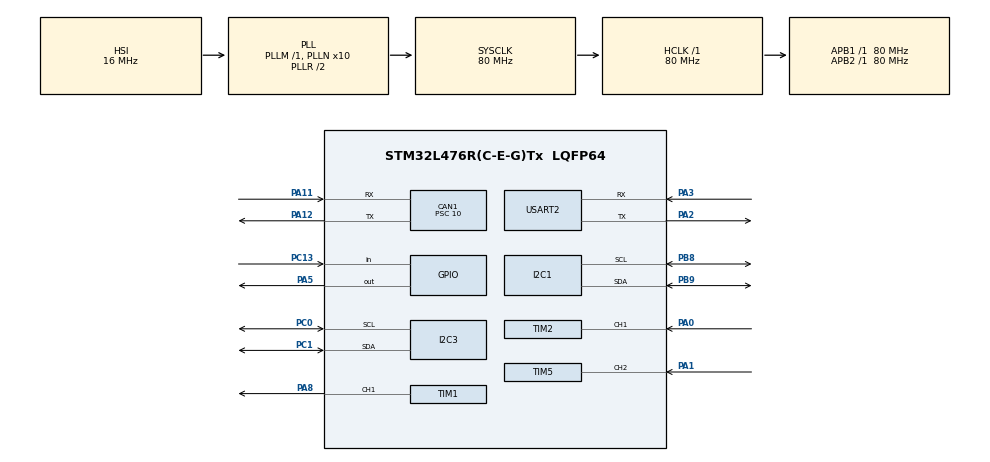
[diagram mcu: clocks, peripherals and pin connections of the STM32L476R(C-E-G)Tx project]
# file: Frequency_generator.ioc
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CAN1.BS1=CAN_BS1_13TQ
CAN1.BS2=CAN_BS2_2TQ
CAN1.CalculateBaudRate=500000
CAN1.CalculateTimeBit=2000.00
CAN1.CalculateTimeQuantum=125.0
CAN1.Prescaler=10
Dma.Request0=TIM2_CH1
Dma.Request1=TIM2_CH2/CH4
Dma.Request2=TIM5_CH1
Dma.Request3=TIM5_CH2
Dma.TIM2_CH1.0.Direction=DMA_PERIPH_TO_MEMORY
Dma.TIM2_CH1.0.Instance=DMA1_Channel5
Dma.TIM2_CH1.0.MemDataAlignment=DMA_MDATAALIGN_WORD
Dma.TIM2_CH1.0.MemInc=DMA_MINC_ENABLE
Dma.TIM2_CH1.0.Mode=DMA_NORMAL
Dma.TIM2_CH1.0.PeriphDataAlignment=DMA_PDATAALIGN_WORD
Dma.TIM2_CH1.0.PeriphInc=DMA_PINC_DISABLE
Dma.TIM2_CH1.0.Priority=DMA_PRIORITY_LOW
Dma.TIM2_CH2/CH4.1.Direction=DMA_PERIPH_TO_MEMORY
Dma.TIM2_CH2/CH4.1.Instance=DMA1_Channel7
Dma.TIM2_CH2/CH4.1.MemDataAlignment=DMA_MDATAALIGN_WORD
Dma.TIM2_CH2/CH4.1.MemInc=DMA_MINC_ENABLE
Dma.TIM2_CH2/CH4.1.Mode=DMA_NORMAL
Dma.TIM2_CH2/CH4.1.PeriphDataAlignment=DMA_PDATAALIGN_WORD
Dma.TIM2_CH2/CH4.1.PeriphInc=DMA_PINC_DISABLE
Dma.TIM2_CH2/CH4.1.Priority=DMA_PRIORITY_LOW
Dma.TIM5_CH1.2.Direction=DMA_PERIPH_TO_MEMORY
Dma.TIM5_CH1.2.Instance=DMA2_Channel5
Dma.TIM5_CH1.2.MemDataAlignment=DMA_MDATAALIGN_WORD
Dma.TIM5_CH1.2.MemInc=DMA_MINC_ENABLE
Dma.TIM5_CH1.2.Mode=DMA_NORMAL
Dma.TIM5_CH1.2.PeriphDataAlignment=DMA_PDATAALIGN_WORD
Dma.TIM5_CH1.2.PeriphInc=DMA_PINC_DISABLE
Dma.TIM5_CH1.2.Priority=DMA_PRIORITY_LOW
Dma.TIM5_CH2.3.Direction=DMA_PERIPH_TO_MEMORY
Dma.TIM5_CH2.3.Instance=DMA2_Channel4
Dma.TIM5_CH2.3.MemDataAlignment=DMA_MDATAALIGN_WORD
Dma.TIM5_CH2.3.MemInc=DMA_MINC_ENABLE
Dma.TIM5_CH2.3.Mode=DMA_NORMAL
Dma.TIM5_CH2.3.PeriphDataAlignment=DMA_PDATAALIGN_WORD
Dma.TIM5_CH2.3.PeriphInc=DMA_PINC_DISABLE
Dma.TIM5_CH2.3.Priority=DMA_PRIORITY_LOW
I2C1.Timing=0x10909CEC
I2C3.Timing=0x10909CEC
Mcu.Family=STM32L4
Mcu.Name=STM32L476R(C-E-G)Tx
Mcu.Package=LQFP64
NVIC.CAN1_RX0_IRQn=true\:0\:0\:false\:false\:true\:true\:true
NVIC.DMA1_Channel5_IRQn=true\:0\:0\:false\:false\:true\:false\:true
NVIC.DMA1_Channel7_IRQn=true\:0\:0\:false\:false\:true\:false\:true
NVIC.DMA2_Channel4_IRQn=true\:0\:0\:false\:false\:true\:false\:true
NVIC.DMA2_Channel5_IRQn=true\:0\:0\:false\:false\:true\:false\:true
NVIC.I2C1_ER_IRQn=true\:0\:0\:false\:false\:true\:true\:true
NVIC.I2C1_EV_IRQn=true\:0\:0\:false\:false\:true\:true\:true
NVIC.PriorityGroup=NVIC_PRIORITYGROUP_4
NVIC.TIM2_IRQn=true\:0\:0\:false\:false\:true\:true\:true
NVIC.TIM5_IRQn=true\:0\:0\:false\:false\:true\:true\:true
PA0.Signal=S_TIM2_CH1
PA1.Signal=S_TIM5_CH2
PA11.Mode=CAN_Activate
PA11.Signal=CAN1_RX
PA12.Mode=CAN_Activate
PA12.Signal=CAN1_TX
PA2.Mode=Asynchronous
PA2.Signal=USART2_TX
PA3.Mode=Asynchronous
PA3.Signal=USART2_RX
PA5.Signal=GPIO_Output
PA8.Signal=S_TIM1_CH1
PB8.Mode=I2C
PB8.Signal=I2C1_SCL
PB9.Mode=I2C
PB9.Signal=I2C1_SDA
PC0.Mode=I2C
PC0.Signal=I2C3_SCL
PC1.Mode=I2C
PC1.Signal=I2C3_SDA
PC13.Signal=GPIO_Input
PC14-OSC32_IN\ (PC14).Mode=LSE-External-Oscillator
PC14-OSC32_IN\ (PC14).Signal=RCC_OSC32_IN
PC15-OSC32_OUT\ (PC15).Mode=LSE-External-Oscillator
PC15-OSC32_OUT\ (PC15).Signal=RCC_OSC32_OUT
ProjectManager.HeapSize=0x200
ProjectManager.StackSize=0x400
ProjectManager.TargetToolchain=SW4STM32
RCC.ADCFreq_Value=64000000
RCC.AHBFreq_Value=80000000
RCC.APB1Freq_Value=80000000
RCC.APB1TimFreq_Value=80000000
RCC.APB2Freq_Value=80000000
RCC.APB2TimFreq_Value=80000000
RCC.CortexFreq_Value=80000000
RCC.HCLKFreq_Value=80000000
RCC.HSE_VALUE=8000000
RCC.HSI_VALUE=16000000
RCC.MSI_VALUE=4000000
RCC.PLLN=10
RCC.PLLSourceVirtual=RCC_PLLSOURCE_HSI
RCC.PREFETCH_ENABLE=1
RCC.RCC_MCO1Source=RCC_MCO1SOURCE_LSI
RCC.RCC_MCODiv=RCC_MCODIV_16
RCC.RTCClockSelection=RCC_RTCCLKSOURCE_LSE
RCC.SYSCLKFreq_VALUE=80000000
RCC.SYSCLKSource=RCC_SYSCLKSOURCE_PLLCLK
RCC.USBFreq_Value=64000000
RCC.VCOOutputFreq_Value=160000000
RTC.Date=7
RTC.Hours=21
RTC.Minutes=30
RTC.Month=RTC_MONTH_AUGUST
RTC.Year=22
SH.S_TIM1_CH1.0=TIM1_CH1,PWM Generation1 CH1
SH.S_TIM2_CH1.0=TIM2_CH1,Input_Capture2_from_TI1
SH.S_TIM2_CH1.1=TIM2_CH1,Input_Capture1_from_TI1
SH.S_TIM5_CH2.0=TIM5_CH2,Input_Capture2_from_TI2
SH.S_TIM5_CH2.1=TIM5_CH2,Input_Capture1_from_TI2
TIM1.Channel-PWM\ Generation1\ CH1=TIM_CHANNEL_1
TIM1.Period=10-1
TIM1.Prescaler=1-1
TIM2.Channel-Input_Capture1_from_TI1=TIM_CHANNEL_1
TIM2.Channel-Input_Capture2_from_TI1=TIM_CHANNEL_2
TIM2.ICPolarity_CH2=TIM_INPUTCHANNELPOLARITY_FALLING
TIM5.Channel-Input_Capture1_from_TI2=TIM_CHANNEL_1
TIM5.Channel-Input_Capture2_from_TI2=TIM_CHANNEL_2
TIM5.ICPolarity_CH1=TIM_INPUTCHANNELPOLARITY_RISING
TIM5.ICPolarity_CH2=TIM_INPUTCHANNELPOLARITY_FALLING
USART2.VirtualMode-Asynchronous=VM_ASYNC
VP_CRC_VS_CRC.Mode=CRC_Activate
VP_RTC_VS_RTC_Activate.Mode=RTC_Enabled
VP_RTC_VS_RTC_Calendar.Mode=RTC_Calendar
VP_TIM1_VS_ClockSourceINT.Mode=Internal
VP_TIM2_VS_ClockSourceINT.Mode=Internal
VP_TIM5_VS_ClockSourceINT.Mode=Internal
board=NUCLEO-L476RG

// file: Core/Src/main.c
/* USER CODE BEGIN Header */
/**
  ******************************************************************************
  * @file           : main.c
  * @brief          : Main program body
  ******************************************************************************
  * @attention
  *
  * <h2><center>&copy; Copyright (c) 2022 STMicroelectronics.
  * All rights reserved.</center></h2>
  *
  * This software component is licensed by ST under BSD 3-Clause license,
  * the "License"; You may not use this file except in compliance with the
  * License. You may obtain a copy of the License at:
  *                        opensource.org/licenses/BSD-3-Clause
  *
  ******************************************************************************
  */
/* USER CODE END Header */
#include "main.h"

CAN_HandleTypeDef hcan1;

CRC_HandleTypeDef hcrc;

I2C_HandleTypeDef hi2c1;
I2C_HandleTypeDef hi2c3;

RTC_HandleTypeDef hrtc;

TIM_HandleTypeDef htim1;
TIM_HandleTypeDef htim2;
TIM_HandleTypeDef htim5;
DMA_HandleTypeDef hdma_tim2_ch1;
DMA_HandleTypeDef hdma_tim2_ch2_ch4;
DMA_HandleTypeDef hdma_tim5_ch1;
DMA_HandleTypeDef hdma_tim5_ch2;

UART_HandleTypeDef huart2;

void SystemClock_Config(void);
static void MX_GPIO_Init(void);
static void MX_DMA_Init(void);
static void MX_USART2_UART_Init(void);
static void MX_TIM2_Init(void);
static void MX_TIM1_Init(void);
static void MX_TIM5_Init(void);
static void MX_I2C1_Init(void);
static void MX_RTC_Init(void);
static void MX_I2C3_Init(void);
static void MX_CRC_Init(void);
static void MX_CAN1_Init(void);

int main(void)
{

  /* MCU Configuration--------------------------------------------------------*/

  /* Reset of all peripherals, Initializes the Flash interface and the Systick. */
  HAL_Init();

  /* Configure the system clock */
  SystemClock_Config();

  /* Initialize all configured peripherals */
  MX_GPIO_Init();
  MX_DMA_Init();
  MX_USART2_UART_Init();
  MX_TIM2_Init();
  MX_TIM1_Init();
  MX_TIM5_Init();
  MX_I2C1_Init();
  MX_RTC_Init();
  MX_I2C3_Init();
  MX_CRC_Init();
  MX_CAN1_Init();
  /* USER CODE BEGIN 2 */
Boot();

  /* USER CODE END 2 */

  /* Infinite loop */
  while (1)
  {

  }
}

void SystemClock_Config(void)
{
  RCC_OscInitTypeDef RCC_OscInitStruct = {0};
  RCC_ClkInitTypeDef RCC_ClkInitStruct = {0};
  RCC_PeriphCLKInitTypeDef PeriphClkInit = {0};

  /** Configure LSE Drive Capability
  */
  HAL_PWR_EnableBkUpAccess();
  __HAL_RCC_LSEDRIVE_CONFIG(RCC_LSEDRIVE_LOW);
  /** Initializes the RCC Oscillators according to the specified parameters
  * in the RCC_OscInitTypeDef structure.
  */
  RCC_OscInitStruct.OscillatorType = RCC_OSCILLATORTYPE_HSI|RCC_OSCILLATORTYPE_LSE;
  RCC_OscInitStruct.LSEState = RCC_LSE_ON;
  RCC_OscInitStruct.HSIState = RCC_HSI_ON;
  RCC_OscInitStruct.HSICalibrationValue = RCC_HSICALIBRATION_DEFAULT;
  RCC_OscInitStruct.PLL.PLLState = RCC_PLL_ON;
  RCC_OscInitStruct.PLL.PLLSource = RCC_PLLSOURCE_HSI;
  RCC_OscInitStruct.PLL.PLLM = 1;
  RCC_OscInitStruct.PLL.PLLN = 10;
  RCC_OscInitStruct.PLL.PLLP = RCC_PLLP_DIV7;
  RCC_OscInitStruct.PLL.PLLQ = RCC_PLLQ_DIV2;
  RCC_OscInitStruct.PLL.PLLR = RCC_PLLR_DIV2;
  if (HAL_RCC_OscConfig(&RCC_OscInitStruct) != HAL_OK)
  {
    Error_Handler();
  }
  /** Initializes the CPU, AHB and APB buses clocks
  */
  RCC_ClkInitStruct.ClockType = RCC_CLOCKTYPE_HCLK|RCC_CLOCKTYPE_SYSCLK
                              |RCC_CLOCKTYPE_PCLK1|RCC_CLOCKTYPE_PCLK2;
  RCC_ClkInitStruct.SYSCLKSource = RCC_SYSCLKSOURCE_PLLCLK;
  RCC_ClkInitStruct.AHBCLKDivider = RCC_SYSCLK_DIV1;
  RCC_ClkInitStruct.APB1CLKDivider = RCC_HCLK_DIV1;
  RCC_ClkInitStruct.APB2CLKDivider = RCC_HCLK_DIV1;

  if (HAL_RCC_ClockConfig(&RCC_ClkInitStruct, FLASH_LATENCY_4) != HAL_OK)
  {
    Error_Handler();
  }
  PeriphClkInit.PeriphClockSelection = RCC_PERIPHCLK_RTC|RCC_PERIPHCLK_USART2
                              |RCC_PERIPHCLK_I2C1|RCC_PERIPHCLK_I2C3;
  PeriphClkInit.Usart2ClockSelection = RCC_USART2CLKSOURCE_PCLK1;
  PeriphClkInit.I2c1ClockSelection = RCC_I2C1CLKSOURCE_PCLK1;
  PeriphClkInit.I2c3ClockSelection = RCC_I2C3CLKSOURCE_PCLK1;
  PeriphClkInit.RTCClockSelection = RCC_RTCCLKSOURCE_LSE;
  if (HAL_RCCEx_PeriphCLKConfig(&PeriphClkInit) != HAL_OK)
  {
    Error_Handler();
  }
  /** Configure the main internal regulator output voltage
  */
  if (HAL_PWREx_ControlVoltageScaling(PWR_REGULATOR_VOLTAGE_SCALE1) != HAL_OK)
  {
    Error_Handler();
  }
}

static void MX_CAN1_Init(void)
{

  hcan1.Instance = CAN1;
  hcan1.Init.Prescaler = 10;
  hcan1.Init.Mode = CAN_MODE_NORMAL;
  hcan1.Init.SyncJumpWidth = CAN_SJW_1TQ;
  hcan1.Init.TimeSeg1 = CAN_BS1_13TQ;
  hcan1.Init.TimeSeg2 = CAN_BS2_2TQ;
  hcan1.Init.TimeTriggeredMode = DISABLE;
  hcan1.Init.AutoBusOff = DISABLE;
  hcan1.Init.AutoWakeUp = DISABLE;
  hcan1.Init.AutoRetransmission = DISABLE;
  hcan1.Init.ReceiveFifoLocked = DISABLE;
  hcan1.Init.TransmitFifoPriority = DISABLE;
  if (HAL_CAN_Init(&hcan1) != HAL_OK)
  {
    Error_Handler();
  }

}

static void MX_CRC_Init(void)
{

  hcrc.Instance = CRC;
  hcrc.Init.DefaultPolynomialUse = DEFAULT_POLYNOMIAL_ENABLE;
  hcrc.Init.DefaultInitValueUse = DEFAULT_INIT_VALUE_ENABLE;
  hcrc.Init.InputDataInversionMode = CRC_INPUTDATA_INVERSION_NONE;
  hcrc.Init.OutputDataInversionMode = CRC_OUTPUTDATA_INVERSION_DISABLE;
  hcrc.InputDataFormat = CRC_INPUTDATA_FORMAT_BYTES;
  if (HAL_CRC_Init(&hcrc) != HAL_OK)
  {
    Error_Handler();
  }

}

static void MX_I2C1_Init(void)
{

  hi2c1.Instance = I2C1;
  hi2c1.Init.Timing = 0x10909CEC;
  hi2c1.Init.OwnAddress1 = 0;
  hi2c1.Init.AddressingMode = I2C_ADDRESSINGMODE_7BIT;
  hi2c1.Init.DualAddressMode = I2C_DUALADDRESS_DISABLE;
  hi2c1.Init.OwnAddress2 = 0;
  hi2c1.Init.OwnAddress2Masks = I2C_OA2_NOMASK;
  hi2c1.Init.GeneralCallMode = I2C_GENERALCALL_DISABLE;
  hi2c1.Init.NoStretchMode = I2C_NOSTRETCH_DISABLE;
  if (HAL_I2C_Init(&hi2c1) != HAL_OK)
  {
    Error_Handler();
  }
  /** Configure Analogue filter
  */
  if (HAL_I2CEx_ConfigAnalogFilter(&hi2c1, I2C_ANALOGFILTER_ENABLE) != HAL_OK)
  {
    Error_Handler();
  }
  /** Configure Digital filter
  */
  if (HAL_I2CEx_ConfigDigitalFilter(&hi2c1, 0) != HAL_OK)
  {
    Error_Handler();
  }

}

static void MX_I2C3_Init(void)
{

  hi2c3.Instance = I2C3;
  hi2c3.Init.Timing = 0x10909CEC;
  hi2c3.Init.OwnAddress1 = 0;
  hi2c3.Init.AddressingMode = I2C_ADDRESSINGMODE_7BIT;
  hi2c3.Init.DualAddressMode = I2C_DUALADDRESS_DISABLE;
  hi2c3.Init.OwnAddress2 = 0;
  hi2c3.Init.OwnAddress2Masks = I2C_OA2_NOMASK;
  hi2c3.Init.GeneralCallMode = I2C_GENERALCALL_DISABLE;
  hi2c3.Init.NoStretchMode = I2C_NOSTRETCH_DISABLE;
  if (HAL_I2C_Init(&hi2c3) != HAL_OK)
  {
    Error_Handler();
  }
  /** Configure Analogue filter
  */
  if (HAL_I2CEx_ConfigAnalogFilter(&hi2c3, I2C_ANALOGFILTER_ENABLE) != HAL_OK)
  {
    Error_Handler();
  }
  /** Configure Digital filter
  */
  if (HAL_I2CEx_ConfigDigitalFilter(&hi2c3, 0) != HAL_OK)
  {
    Error_Handler();
  }

}

static void MX_RTC_Init(void)
{

  RTC_TimeTypeDef sTime = {0};
  RTC_DateTypeDef sDate = {0};

  /** Initialize RTC Only
  */
  hrtc.Instance = RTC;
  hrtc.Init.HourFormat = RTC_HOURFORMAT_24;
  hrtc.Init.AsynchPrediv = 127;
  hrtc.Init.SynchPrediv = 255;
  hrtc.Init.OutPut = RTC_OUTPUT_DISABLE;
  hrtc.Init.OutPutRemap = RTC_OUTPUT_REMAP_NONE;
  hrtc.Init.OutPutPolarity = RTC_OUTPUT_POLARITY_HIGH;
  hrtc.Init.OutPutType = RTC_OUTPUT_TYPE_OPENDRAIN;
  if (HAL_RTC_Init(&hrtc) != HAL_OK)
  {
    Error_Handler();
  }

  /** Initialize RTC and set the Time and Date
  */
  sTime.Hours = 0x21;
  sTime.Minutes = 0x30;
  sTime.Seconds = 0x0;
  sTime.DayLightSaving = RTC_DAYLIGHTSAVING_NONE;
  sTime.StoreOperation = RTC_STOREOPERATION_RESET;
  if (HAL_RTC_SetTime(&hrtc, &sTime, RTC_FORMAT_BCD) != HAL_OK)
  {
    Error_Handler();
  }
  sDate.WeekDay = RTC_WEEKDAY_MONDAY;
  sDate.Month = RTC_MONTH_AUGUST;
  sDate.Date = 0x7;
  sDate.Year = 0x22;

  if (HAL_RTC_SetDate(&hrtc, &sDate, RTC_FORMAT_BCD) != HAL_OK)
  {
    Error_Handler();
  }

}

static void MX_TIM1_Init(void)
{

  TIM_ClockConfigTypeDef sClockSourceConfig = {0};
  TIM_MasterConfigTypeDef sMasterConfig = {0};
  TIM_OC_InitTypeDef sConfigOC = {0};
  TIM_BreakDeadTimeConfigTypeDef sBreakDeadTimeConfig = {0};

  htim1.Instance = TIM1;
  htim1.Init.Prescaler = 1-1;
  htim1.Init.CounterMode = TIM_COUNTERMODE_UP;
  htim1.Init.Period = 10-1;
  htim1.Init.ClockDivision = TIM_CLOCKDIVISION_DIV1;
  htim1.Init.RepetitionCounter = 0;
  htim1.Init.AutoReloadPreload = TIM_AUTORELOAD_PRELOAD_DISABLE;
  if (HAL_TIM_Base_Init(&htim1) != HAL_OK)
  {
    Error_Handler();
  }
  sClockSourceConfig.ClockSource = TIM_CLOCKSOURCE_INTERNAL;
  if (HAL_TIM_ConfigClockSource(&htim1, &sClockSourceConfig) != HAL_OK)
  {
    Error_Handler();
  }
  if (HAL_TIM_PWM_Init(&htim1) != HAL_OK)
  {
    Error_Handler();
  }
  sMasterConfig.MasterOutputTrigger = TIM_TRGO_RESET;
  sMasterConfig.MasterOutputTrigger2 = TIM_TRGO2_RESET;
  sMasterConfig.MasterSlaveMode = TIM_MASTERSLAVEMODE_DISABLE;
  if (HAL_TIMEx_MasterConfigSynchronization(&htim1, &sMasterConfig) != HAL_OK)
  {
    Error_Handler();
  }
  sConfigOC.OCMode = TIM_OCMODE_PWM1;
  sConfigOC.Pulse = 0;
  sConfigOC.OCPolarity = TIM_OCPOLARITY_HIGH;
  sConfigOC.OCNPolarity = TIM_OCNPOLARITY_HIGH;
  sConfigOC.OCFastMode = TIM_OCFAST_DISABLE;
  sConfigOC.OCIdleState = TIM_OCIDLESTATE_RESET;
  sConfigOC.OCNIdleState = TIM_OCNIDLESTATE_RESET;
  if (HAL_TIM_PWM_ConfigChannel(&htim1, &sConfigOC, TIM_CHANNEL_1) != HAL_OK)
  {
    Error_Handler();
  }
  sBreakDeadTimeConfig.OffStateRunMode = TIM_OSSR_DISABLE;
  sBreakDeadTimeConfig.OffStateIDLEMode = TIM_OSSI_DISABLE;
  sBreakDeadTimeConfig.LockLevel = TIM_LOCKLEVEL_OFF;
  sBreakDeadTimeConfig.DeadTime = 0;
  sBreakDeadTimeConfig.BreakState = TIM_BREAK_DISABLE;
  sBreakDeadTimeConfig.BreakPolarity = TIM_BREAKPOLARITY_HIGH;
  sBreakDeadTimeConfig.BreakFilter = 0;
  sBreakDeadTimeConfig.Break2State = TIM_BREAK2_DISABLE;
  sBreakDeadTimeConfig.Break2Polarity = TIM_BREAK2POLARITY_HIGH;
  sBreakDeadTimeConfig.Break2Filter = 0;
  sBreakDeadTimeConfig.AutomaticOutput = TIM_AUTOMATICOUTPUT_DISABLE;
  if (HAL_TIMEx_ConfigBreakDeadTime(&htim1, &sBreakDeadTimeConfig) != HAL_OK)
  {
    Error_Handler();
  }
  HAL_TIM_MspPostInit(&htim1);

}

static void MX_TIM2_Init(void)
{

  TIM_ClockConfigTypeDef sClockSourceConfig = {0};
  TIM_MasterConfigTypeDef sMasterConfig = {0};
  TIM_IC_InitTypeDef sConfigIC = {0};

  htim2.Instance = TIM2;
  htim2.Init.Prescaler = 0;
  htim2.Init.CounterMode = TIM_COUNTERMODE_UP;
  htim2.Init.Period = 4294967295;
  htim2.Init.ClockDivision = TIM_CLOCKDIVISION_DIV1;
  htim2.Init.AutoReloadPreload = TIM_AUTORELOAD_PRELOAD_DISABLE;
  if (HAL_TIM_Base_Init(&htim2) != HAL_OK)
  {
    Error_Handler();
  }
  sClockSourceConfig.ClockSource = TIM_CLOCKSOURCE_INTERNAL;
  if (HAL_TIM_ConfigClockSource(&htim2, &sClockSourceConfig) != HAL_OK)
  {
    Error_Handler();
  }
  if (HAL_TIM_IC_Init(&htim2) != HAL_OK)
  {
    Error_Handler();
  }
  sMasterConfig.MasterOutputTrigger = TIM_TRGO_RESET;
  sMasterConfig.MasterSlaveMode = TIM_MASTERSLAVEMODE_DISABLE;
  if (HAL_TIMEx_MasterConfigSynchronization(&htim2, &sMasterConfig) != HAL_OK)
  {
    Error_Handler();
  }
  sConfigIC.ICPolarity = TIM_INPUTCHANNELPOLARITY_RISING;
  sConfigIC.ICSelection = TIM_ICSELECTION_DIRECTTI;
  sConfigIC.ICPrescaler = TIM_ICPSC_DIV1;
  sConfigIC.ICFilter = 0;
  if (HAL_TIM_IC_ConfigChannel(&htim2, &sConfigIC, TIM_CHANNEL_1) != HAL_OK)
  {
    Error_Handler();
  }
  sConfigIC.ICPolarity = TIM_INPUTCHANNELPOLARITY_FALLING;
  sConfigIC.ICSelection = TIM_ICSELECTION_INDIRECTTI;
  if (HAL_TIM_IC_ConfigChannel(&htim2, &sConfigIC, TIM_CHANNEL_2) != HAL_OK)
  {
    Error_Handler();
  }

}

static void MX_TIM5_Init(void)
{

  TIM_ClockConfigTypeDef sClockSourceConfig = {0};
  TIM_MasterConfigTypeDef sMasterConfig = {0};
  TIM_IC_InitTypeDef sConfigIC = {0};

  htim5.Instance = TIM5;
  htim5.Init.Prescaler = 0;
  htim5.Init.CounterMode = TIM_COUNTERMODE_UP;
  htim5.Init.Period = 4294967295;
  htim5.Init.ClockDivision = TIM_CLOCKDIVISION_DIV1;
  htim5.Init.AutoReloadPreload = TIM_AUTORELOAD_PRELOAD_DISABLE;
  if (HAL_TIM_Base_Init(&htim5) != HAL_OK)
  {
    Error_Handler();
  }
  sClockSourceConfig.ClockSource = TIM_CLOCKSOURCE_INTERNAL;
  if (HAL_TIM_ConfigClockSource(&htim5, &sClockSourceConfig) != HAL_OK)
  {
    Error_Handler();
  }
  if (HAL_TIM_IC_Init(&htim5) != HAL_OK)
  {
    Error_Handler();
  }
  sMasterConfig.MasterOutputTrigger = TIM_TRGO_RESET;
  sMasterConfig.MasterSlaveMode = TIM_MASTERSLAVEMODE_DISABLE;
  if (HAL_TIMEx_MasterConfigSynchronization(&htim5, &sMasterConfig) != HAL_OK)
  {
    Error_Handler();
  }
  sConfigIC.ICPolarity = TIM_INPUTCHANNELPOLARITY_RISING;
  sConfigIC.ICSelection = TIM_ICSELECTION_INDIRECTTI;
  sConfigIC.ICPrescaler = TIM_ICPSC_DIV1;
  sConfigIC.ICFilter = 0;
  if (HAL_TIM_IC_ConfigChannel(&htim5, &sConfigIC, TIM_CHANNEL_1) != HAL_OK)
  {
    Error_Handler();
  }
  sConfigIC.ICPolarity = TIM_INPUTCHANNELPOLARITY_FALLING;
  sConfigIC.ICSelection = TIM_ICSELECTION_DIRECTTI;
  if (HAL_TIM_IC_ConfigChannel(&htim5, &sConfigIC, TIM_CHANNEL_2) != HAL_OK)
  {
    Error_Handler();
  }

}

static void MX_USART2_UART_Init(void)
{

  huart2.Instance = USART2;
  huart2.Init.BaudRate = 115200;
  huart2.Init.WordLength = UART_WORDLENGTH_8B;
  huart2.Init.StopBits = UART_STOPBITS_1;
  huart2.Init.Parity = UART_PARITY_NONE;
  huart2.Init.Mode = UART_MODE_TX_RX;
  huart2.Init.HwFlowCtl = UART_HWCONTROL_NONE;
  huart2.Init.OverSampling = UART_OVERSAMPLING_16;
  huart2.Init.OneBitSampling = UART_ONE_BIT_SAMPLE_DISABLE;
  huart2.AdvancedInit.AdvFeatureInit = UART_ADVFEATURE_NO_INIT;
  if (HAL_UART_Init(&huart2) != HAL_OK)
  {
    Error_Handler();
  }

}

static void MX_DMA_Init(void)
{

  /* DMA controller clock enable */
  __HAL_RCC_DMA1_CLK_ENABLE();
  __HAL_RCC_DMA2_CLK_ENABLE();

  /* DMA interrupt init */
  /* DMA1_Channel5_IRQn interrupt configuration */
  HAL_NVIC_SetPriority(DMA1_Channel5_IRQn, 0, 0);
  HAL_NVIC_EnableIRQ(DMA1_Channel5_IRQn);
  /* DMA1_Channel7_IRQn interrupt configuration */
  HAL_NVIC_SetPriority(DMA1_Channel7_IRQn, 0, 0);
  HAL_NVIC_EnableIRQ(DMA1_Channel7_IRQn);
  /* DMA2_Channel4_IRQn interrupt configuration */
  HAL_NVIC_SetPriority(DMA2_Channel4_IRQn, 0, 0);
  HAL_NVIC_EnableIRQ(DMA2_Channel4_IRQn);
  /* DMA2_Channel5_IRQn interrupt configuration */
  HAL_NVIC_SetPriority(DMA2_Channel5_IRQn, 0, 0);
  HAL_NVIC_EnableIRQ(DMA2_Channel5_IRQn);

}

static void MX_GPIO_Init(void)
{
  GPIO_InitTypeDef GPIO_InitStruct = {0};

  /* GPIO Ports Clock Enable */
  __HAL_RCC_GPIOC_CLK_ENABLE();
  __HAL_RCC_GPIOA_CLK_ENABLE();
  __HAL_RCC_GPIOB_CLK_ENABLE();

  /*Configure GPIO pin Output Level */
  HAL_GPIO_WritePin(GPIOA, GPIO_PIN_5, GPIO_PIN_RESET);

  /*Configure GPIO pin : PC13 */
  GPIO_InitStruct.Pin = GPIO_PIN_13;
  GPIO_InitStruct.Mode = GPIO_MODE_INPUT;
  GPIO_InitStruct.Pull = GPIO_NOPULL;
  HAL_GPIO_Init(GPIOC, &GPIO_InitStruct);

  /*Configure GPIO pin : PA5 */
  GPIO_InitStruct.Pin = GPIO_PIN_5;
  GPIO_InitStruct.Mode = GPIO_MODE_OUTPUT_PP;
  GPIO_InitStruct.Pull = GPIO_NOPULL;
  GPIO_InitStruct.Speed = GPIO_SPEED_FREQ_LOW;
  HAL_GPIO_Init(GPIOA, &GPIO_InitStruct);

}

void Error_Handler(void)
{
  __disable_irq();
  while (1)
  {
  }
}

/************************ (C) COPYRIGHT STMicroelectronics *****END OF FILE****/
